VERSION ""

NS_ :

BS_:

BU_: MS6_Logger_CAN_Bus_1

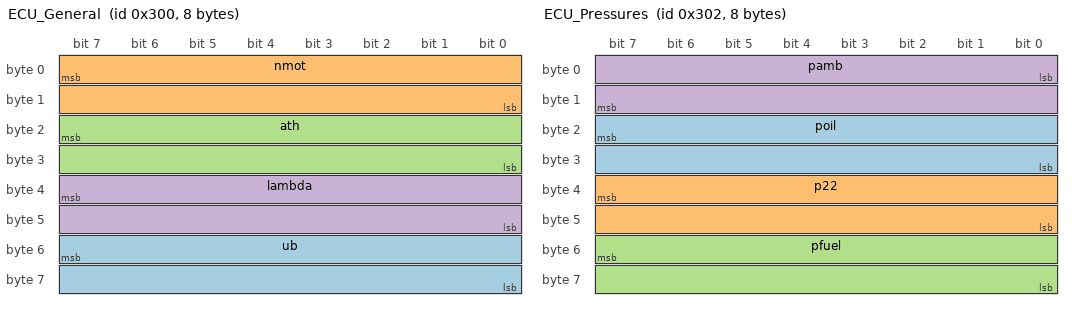
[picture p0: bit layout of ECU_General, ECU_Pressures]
BO_ 768 ECU_General: 8 MS6_Logger_CAN_Bus_1
 SG_ ub : 55|16@0- (0.01,0) [0|25.5] "V" Vector__XXX
 SG_ nmot : 7|16@0- (1,0) [0|20000] "rpm" Vector__XXX
 SG_ ath : 23|16@0- (0.1,0) [0|110] "%" Vector__XXX
 SG_ lambda : 39|16@0- (0.001,0) [0|5] "" Vector__XXX

BO_ 770 ECU_Pressures: 8 MS6_Logger_CAN_Bus_1
 SG_ poil : 23|16@0- (0.001,0) [0|10] "bar" Vector__XXX
 SG_ p22 : 39|16@0- (1,0) [0|5000] "mbar" Vector__XXX
 SG_ pfuel : 55|16@0- (0.001,0) [0|10] "bar" Vector__XXX
 SG_ pamb : 0|16@1+ (0.1,0) [0|2000] "mbar" Vector__XXX

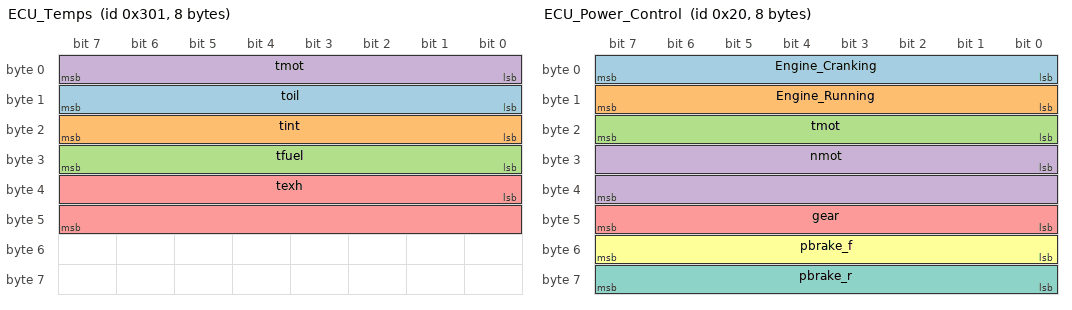
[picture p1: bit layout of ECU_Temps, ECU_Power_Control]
BO_ 769 ECU_Temps: 8 MS6_Logger_CAN_Bus_1
 SG_ toil : 15|8@0+ (1,0) [60|150] "°C" Vector__XXX
 SG_ tint : 23|8@0+ (1,0) [10|60] "°C" Vector__XXX
 SG_ tfuel : 31|8@0+ (1,0) [10|80] "°C" Vector__XXX
 SG_ tmot : 0|8@1+ (1,0) [40|120] "°C" Vector__XXX
 SG_ texh : 32|16@1+ (1,0) [0|1250] "°C" Vector__XXX

BO_ 32 ECU_Power_Control: 8 MS6_Logger_CAN_Bus_1
 SG_ Engine_Cranking : 0|8@1+ (1,0) [0|1] "" Vector__XXX
 SG_ Engine_Running : 8|8@1+ (1,0) [0|1] "" Vector__XXX
 SG_ tmot : 16|8@1+ (1,0) [40|120] "°C" Vector__XXX
 SG_ nmot : 24|16@1+ (1,0) [0|20000] "rpm" Vector__XXX
 SG_ gear : 40|8@1- (1,0) [-1|12] "" Vector__XXX
 SG_ pbrake_f : 48|8@1+ (1,0) [0|150] "bar" Vector__XXX
 SG_ pbrake_r : 56|8@1+ (1,0) [0|150] "bar" Vector__XXX

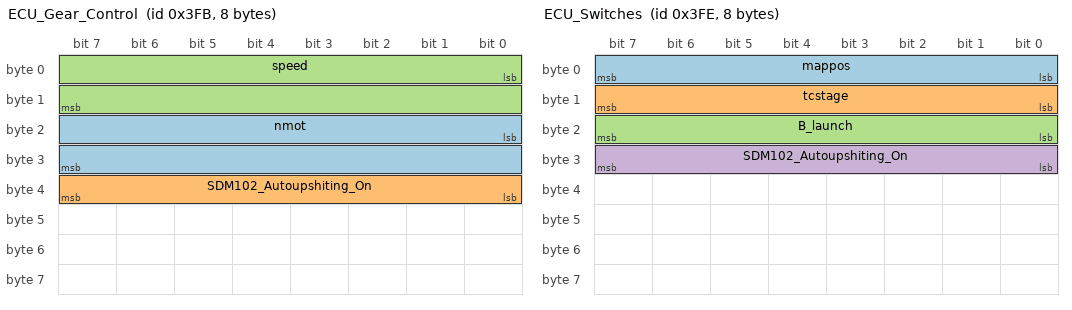
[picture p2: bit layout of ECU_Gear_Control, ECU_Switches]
BO_ 1019 ECU_Gear_Control: 8 MS6_Logger_CAN_Bus_1
 SG_ nmot : 16|16@1- (1,0) [0|20000] "rpm" Vector__XXX
 SG_ SDM102_Autoupshiting_On : 32|8@1+ (1,0) [0|1] "" Vector__XXX
 SG_ speed : 0|16@1+ (0.01,0) [0|400] "km/h" Vector__XXX

BO_ 1568 ECU_INT_Sw_Rot_01_SDM102: 8 MS6_Logger_CAN_Bus_1
 SG_ SDM102_ECU_Map : 8|8@1+ (1,0) [0|0] "" Vector__XXX
 SG_ SDM102_Tract_Ctrl : 40|8@1+ (1,0) [0|0] "" Vector__XXX

BO_ 1576 ECU_INT_Sw_Bin_01_SDM102: 8 MS6_Logger_CAN_Bus_1
 SG_ SDM102_Launch_Ctrl_On : 3|1@1+ (1,0) [0|1] "" Vector__XXX

BO_ 1022 ECU_Switches: 8 MS6_Logger_CAN_Bus_1
 SG_ mappos : 0|8@1+ (1,0) [0|15] "" Vector__XXX
 SG_ tcstage : 8|8@1+ (1,0) [0|12] "" Vector__XXX
 SG_ B_launch : 16|8@1+ (1,0) [0|1] "" Vector__XXX
 SG_ SDM102_Autoupshiting_On : 24|8@1+ (1,0) [0|1] "" Vector__XXX

BO_ 1690 ECU_Lap_Times: 8 MS6_Logger_CAN_Bus_1
 SG_ Laptrigger_laptimeold_dls : 0|32@1+ (0.01,0) [0|500] "s" Vector__XXX
 SG_ Laptrigger_laptime_dls : 32|32@1+ (0.01,0) [0|500] "s" Vector__XXX

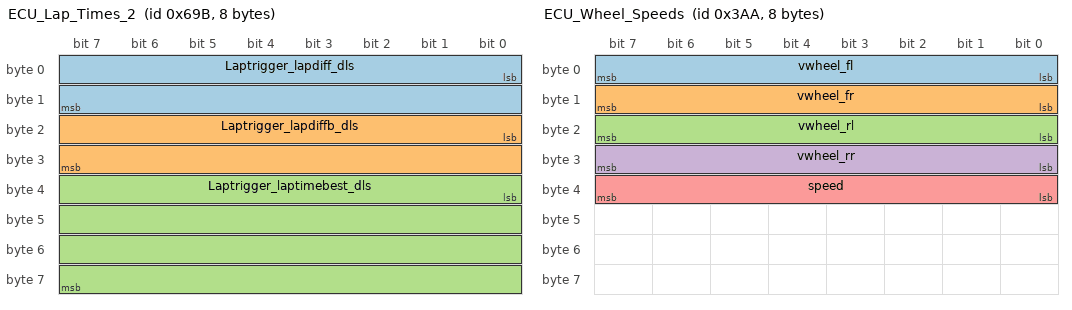
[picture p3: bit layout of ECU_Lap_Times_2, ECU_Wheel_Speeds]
BO_ 1691 ECU_Lap_Times_2: 8 MS6_Logger_CAN_Bus_1
 SG_ Laptrigger_lapdiff_dls : 0|16@1- (0.01,0) [-20|20] "s" Vector__XXX
 SG_ Laptrigger_lapdiffb_dls : 16|16@1- (0.01,0) [-20|20] "s" Vector__XXX
 SG_ Laptrigger_laptimebest_dls : 32|32@1+ (0.01,0) [0|500] "s" Vector__XXX

BO_ 1692 ECU_Lap_Times_3: 8 MS6_Logger_CAN_Bus_1
 SG_ lapctr : 0|8@1+ (1,0) [0|255] "" Vector__XXX
 SG_ outctr : 8|8@1+ (1,0) [0|255] "" Vector__XXX

BO_ 938 ECU_Wheel_Speeds: 8 MS6_Logger_CAN_Bus_1
 SG_ vwheel_fl : 0|8@1+ (1,0) [0|400] "km/h" Vector__XXX
 SG_ vwheel_fr : 8|8@1+ (1,0) [0|400] "km/h" Vector__XXX
 SG_ vwheel_rl : 16|8@1+ (1,0) [0|400] "km/h" Vector__XXX
 SG_ vwheel_rr : 24|8@1+ (1,0) [0|400] "km/h" Vector__XXX
 SG_ speed : 32|8@1+ (1,0) [0|400] "km/h" Vector__XXX

BO_ 592 ECU_Autoupshifting_Targets_1: 8 MS6_Logger_CAN_Bus_1

BO_ 594 ECU_Autoupshifting_Targets_3: 8 MS6_Logger_CAN_Bus_1

BO_ 593 ECU_Autoupshifting_Targets_2: 8 MS6_Logger_CAN_Bus_1

CM_ BO_ 768 "RPM, Throttle Position, Lambda, Battery Voltage";
CM_ SG_ 768 ub "battery voltage";
CM_ SG_ 768 nmot "engine speed";
CM_ SG_ 768 ath "throttle position";
CM_ SG_ 768 lambda "Lambda actual value";
CM_ BO_ 770 "Ambient Pressure, Oil Pressure, Manifold Pressure, Fuel Pressure";
CM_ SG_ 770 poil "oil pressure";
CM_ SG_ 770 p22 "intake manifold pressure downstream throttle";
CM_ SG_ 770 pfuel "fuel pressure";
CM_ SG_ 770 pamb "ambient pressure";
CM_ BO_ 769 "Coolant Temp, Oil Temp, Manifold Temp, Fuel Temp, Exhaust Temp";
CM_ SG_ 769 toil "oil temperature";
CM_ SG_ 769 tint "intake air temperature";
CM_ SG_ 769 tfuel "fuel temperature";
CM_ SG_ 769 tmot "engine temperature";
CM_ SG_ 769 texh "exhaust gas temperature";
CM_ BO_ 32 "Engine_Cranking, Engine_Running, tmot, nmot, gear, pbrake_f, pbrake_r";
CM_ SG_ 32 Engine_Cranking "Returns true, if (1 <= nmot <= 1000)";
CM_ SG_ 32 Engine_Running "Returns true, if (nmot > 0)";
CM_ SG_ 32 tmot "engine temperature";
CM_ SG_ 32 nmot "engine speed";
CM_ SG_ 32 gear "selected gear";
CM_ SG_ 32 pbrake_f "brake pressure front ";
CM_ SG_ 32 pbrake_r "brake pressure rear";
CM_ BO_ 1019 "Ground Speed, RPM, Auto-upshifting Enable";
CM_ SG_ 1019 nmot "engine speed";
CM_ SG_ 1019 SDM102_Autoupshiting_On "Returns true, if (SDM102_Launch_Ctrl_And_Autoupshifting_Pre or SDM102_Autoupshifting_Only_Pre_1 or SDM102_Autoupshifting_Only_Pre_2)";
CM_ SG_ 1019 speed "car speed";
CM_ BO_ 1568 "Traction Control + ECU Map from SDM 102 Knobs (Internal Redirect)";
CM_ BO_ 1576 "Launch Control from SDM 102 Knob (Internal Redirect)";
CM_ SG_ 1576 SDM102_Launch_Ctrl_On "Returns true, if (SDM102_Launch_Ctrl_Only_Pre or SDM102_Launch_Ctrl_And_Autoupshifting_Pre)";
CM_ BO_ 1022 "Map Position, TC Stage, Launch Control, Auto-upshifting";
CM_ SG_ 1022 mappos "position of map switch";
CM_ SG_ 1022 tcstage "traction control stage";
CM_ SG_ 1022 B_launch "condition launch control active";
CM_ SG_ 1022 SDM102_Autoupshiting_On "Returns true, if (SDM102_Launch_Ctrl_And_Autoupshifting_Pre or SDM102_Autoupshifting_Only_Pre_1 or SDM102_Autoupshifting_Only_Pre_2)";
CM_ BO_ 1690 "Previous Lap Time, Current Lap Time";
CM_ SG_ 1690 Laptrigger_laptimeold_dls "previous lap time";
CM_ SG_ 1690 Laptrigger_laptime_dls "running lap time";
CM_ BO_ 1691 "Lap Differences, Best Lap";
CM_ SG_ 1691 Laptrigger_lapdiff_dls "lapdiff to last";
CM_ SG_ 1691 Laptrigger_lapdiffb_dls "lapdiff to best";
CM_ SG_ 1691 Laptrigger_laptimebest_dls "best lap time";
CM_ BO_ 1692 "Lap Counter, Out Counter";
CM_ SG_ 1692 lapctr "lap counter";
CM_ SG_ 1692 outctr "current outing";
CM_ BO_ 938 "FL/FR/RL/RR Wheel Speeds, Ground Speed";
CM_ SG_ 938 vwheel_fl "wheel speed front left";
CM_ SG_ 938 vwheel_fr "wheel speed front right";
CM_ SG_ 938 vwheel_rl "wheel speed rear left";
CM_ SG_ 938 vwheel_rr "wheel speed rear right";
CM_ SG_ 938 speed "car speed";
CM_ BO_ 592 "Target RPMs from 1 to 4";
CM_ BO_ 594 "Target RPM + speed for 5";
CM_ BO_ 593 "Target speeds from 1 to 4";
